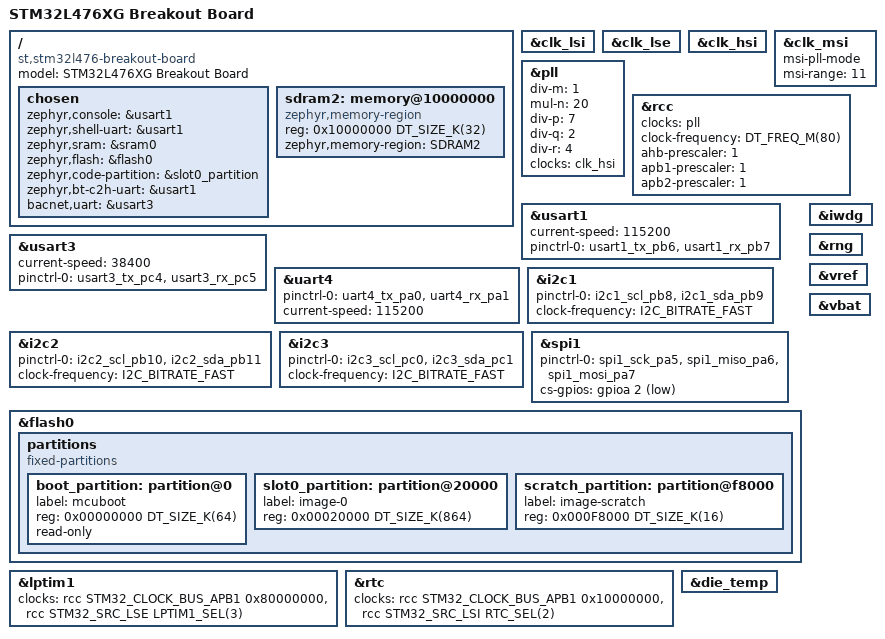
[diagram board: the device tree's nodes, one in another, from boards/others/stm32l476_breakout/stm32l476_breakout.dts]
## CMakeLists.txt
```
# SPDX-License-Identifier: Apache-2.0

set(SHIELD adafruit_2_8_tft_touch_v2)

cmake_minimum_required(VERSION 3.20.0)

# would be dope to define DBOARD_ROOT in here

find_package(Zephyr REQUIRED HINTS $ENV{ZEPHYR_BASE})
project(snowboard_press)

target_sources(app PRIVATE src/main.c)
target_sources(app PRIVATE src/console_cmds.c)

# Add custom linker section to relocate framebuffers to SRAM2
zephyr_linker_sources_ifdef(CONFIG_LV_Z_VBD_CUSTOM_SECTION
  SECTIONS dc_ram.ld)
```

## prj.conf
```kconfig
CONFIG_DEBUG=y

# peripherals
CONFIG_GPIO=y
CONFIG_I2C=y
CONFIG_SPI=y
CONFIG_SERIAL=y # from Modbus sample
CONFIG_UART_INTERRUPT_DRIVEN=y # from UART sample - needs serial interrupt enabled?
CONFIG_UART_LINE_CTRL=n # "Say no if not sure" so says zephyr documentation
CONFIG_UART_WIDE_DATA=y # BACNet messages are uint16


# log
CONFIG_LOG=y
#CONFIG_LOG_PRINTK=y
#CONFIG_LOG_MODE_IMMEDIATE=y

# shell / console
CONFIG_SHELL=y
CONFIG_GPIO_SHELL=y
CONFIG_I2C_SHELL=y
CONFIG_SPI_SHELL=y
CONFIG_STDOUT_CONSOLE=y
CONFIG_CONSOLE=y
CONFIG_PRINTK=y

# display / graphics
CONFIG_LVGL=y
CONFIG_LV_MEM_CUSTOM=y
CONFIG_LV_USE_LOG=y
CONFIG_LV_USE_LABEL=y
CONFIG_LV_USE_BTN=y
CONFIG_LV_USE_ARC=y
CONFIG_LV_USE_IMG=y
CONFIG_LV_USE_MONKEY=y
CONFIG_LV_FONT_MONTSERRAT_14=y
CONFIG_LV_Z_MEM_POOL_SIZE=16384
CONFIG_LV_Z_SHELL=y
CONFIG_MAIN_STACK_SIZE=2048
CONFIG_DISPLAY=y
CONFIG_DISPLAY_LOG_LEVEL_ERR=y

# Enable polling used by the event mechanism
#CONFIG_POLL=y

# Enable the state machine framework
#CONFIG_SMF=y
#CONFIG_SMF_ANCESTOR_SUPPORT=y
#CONFIG_SMF_INITIAL_TRANSITION=y

# Enable thread awareness for debugging tools supporting it
#CONFIG_DEBUG_THREAD_INFO=y

# enable to use thread names
#CONFIG_THREAD_NAME=y

# these configs imported from board_test_cli
#CONFIG_THREAD_MONITOR=y 
#CONFIG_INIT_STACKS=y 
CONFIG_BOOT_BANNER=y # this was n for board_test_cli
#CONFIG_THREAD_NAME=y 
#CONFIG_CBPRINTF_NANO=y
```

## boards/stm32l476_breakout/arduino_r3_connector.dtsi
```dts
/*
 * Copyright (c) 2019 Linaro Limited
 *
 * SPDX-License-Identifier: Apache-2.0
 */

/ {
	arduino_header: connector {
		compatible = "arduino-header-r3";
		#gpio-cells = <2>;
		gpio-map-mask = <0xffffffff 0xffffffc0>;
		gpio-map-pass-thru = <0 0x3f>;
		gpio-map = <0 0 &gpioc 5 0>,	/* A0 */
			   <1 0 &gpioc 4 0>,	/* A1 */
			   <2 0 &gpioc 3 0>,	/* A2 */
			   <3 0 &gpioc 2 0>,	/* A3 */
			   <4 0 &gpioc 1 0>,	/* A4 */
			   <5 0 &gpioc 0 0>,	/* A5 */
			   <6 0 &gpioa 1 0>,	/* D0 */
			   <7 0 &gpioa 0 0>,	/* D1 */
			   <8 0 &gpiod 14 0>,	/* D2 */
			   <9 0 &gpiob 0 0>,	/* D3 */
			   <10 0 &gpioa 3 0>,	/* D4 */
			   <11 0 &gpiob 4 0>,	/* D5 */
			   <12 0 &gpiob 1 0>,	/* D6 */
			   <13 0 &gpioc 7 0>,	/* D7 - MOVED FROM PA4 TO PC7 */
			   <14 0 &gpiob 12 0>,	/* D8 - MOVED FROM PB2 TO PB12 */
			   <15 0 &gpioa 15 0>,	/* D9 */
			   <16 0 &gpioa 2 0>,	/* D10 */
			   <17 0 &gpioa 7 0>,	/* D11 */
			   <18 0 &gpioa 6 0>,	/* D12 */
			   <19 0 &gpioa 5 0>,	/* D13 */
			   <20 0 &gpiob 9 0>,	/* D14 */
			   <21 0 &gpiob 8 0>;	/* D15 */
	};
};

arduino_i2c: &i2c1 {};
arduino_spi: &spi1 {};
arduino_serial: &uart4 {};
```

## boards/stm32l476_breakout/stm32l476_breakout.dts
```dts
/*
 * By Sam Burner 2025/06/18
 *
 * SPDX-License-Identifier: Apache-2.0
 */

 /dts-v1/;
#include <st\l4\stm32l476Xg.dtsi>
#include <st\l4\stm32l476r(c-e-g)tx-pinctrl.dtsi>
#include "arduino_r3_connector.dtsi"
#include <zephyr/dt-bindings/input/input-event-codes.h>

/ {
    model = "STM32L476XG Breakout Board";
    compatible = "st,stm32l476-breakout-board"; /* not sure if the "st," is an issue? possibly defined by vendor in yaml files */

    chosen {
		zephyr,console = &usart1;
		zephyr,shell-uart = &usart1;
		zephyr,sram = &sram0;
		zephyr,flash = &flash0;
		zephyr,code-partition = &slot0_partition;
		zephyr,bt-c2h-uart = &usart1; /* probably unnecessary */
	};

};

&clk_lsi {
	status = "okay";
};

&clk_lse {
	status = "okay";
};

&clk_hsi {
	status = "okay";
};

/* probably unnecessary, hopefully not a problem */
&clk_msi {
	status = "okay";
	msi-pll-mode;
	msi-range = <11>; /* 48MHz USB bus clk */
};

&pll {
	div-m = <1>;
	mul-n = <20>;
	div-p = <7>;
	div-q = <2>;
	div-r = <4>;
	clocks = <&clk_hsi>;
	status = "okay";
};

&rcc {
	clocks = <&pll>;
	clock-frequency = <DT_FREQ_M(80)>;
	ahb-prescaler = <1>;
	apb1-prescaler = <1>;
	apb2-prescaler = <1>;
};

&usart1 {
	current-speed = <115200>;
	pinctrl-0 = <&usart1_tx_pb6 &usart1_rx_pb7>;
	pinctrl-names = "default";
	status = "okay";
};

&usart3 {
	current-speed = <115200>;
	pinctrl-0 = <&usart3_tx_pc4 &usart3_rx_pc5>;
	pinctrl-names = "default";
	status = "okay";
};

&uart4 {
	pinctrl-0 = <&uart4_tx_pa0 &uart4_rx_pa1>;
	pinctrl-names = "default";
	current-speed = <115200>;
	status = "okay";
};

&i2c1 {
	pinctrl-0 = <&i2c1_scl_pb8 &i2c1_sda_pb9>;
	pinctrl-names = "default";
	status = "okay";
	clock-frequency = <I2C_BITRATE_FAST>;
};

&i2c2 {
	pinctrl-0 = <&i2c2_scl_pb10 &i2c2_sda_pb11>;
	pinctrl-names = "default";
	status = "okay";
	clock-frequency = <I2C_BITRATE_FAST>;
};

&i2c3 {
	pinctrl-0 = <&i2c3_scl_pc0 &i2c3_sda_pc1>;
	pinctrl-names = "default";
	status = "okay";
	clock-frequency = <I2C_BITRATE_FAST>;
};

&spi1 {
	pinctrl-0 = <&spi1_sck_pa5 &spi1_miso_pa6 &spi1_mosi_pa7>;
	pinctrl-names = "default";
	cs-gpios = <&gpioa 2 (GPIO_ACTIVE_LOW | GPIO_PULL_UP)>;
	status = "okay";
};

&flash0 {
	partitions {
		compatible = "fixed-partitions";
		#address-cells = <1>;
		#size-cells = <1>;

		boot_partition: partition@0 {
			label = "mcuboot";
			reg = <0x00000000 DT_SIZE_K(64)>;
			read-only;
		};

		/*
		 * The flash starting at offset 0x10000 and ending at
		 * offset 0x1ffff is reserved for use by the application.
		 */

		slot0_partition: partition@20000 {
			label = "image-0";
			reg = <0x00020000 DT_SIZE_K(864)>;
		};

		scratch_partition: partition@f8000 {
			label = "image-scratch";
			reg = <0x000F8000 DT_SIZE_K(16)>;
		};
	};
};

stm32_lp_tick_source: &lptim1 {
	clocks = <&rcc STM32_CLOCK_BUS_APB1 0x80000000>,
		 <&rcc STM32_SRC_LSE LPTIM1_SEL(3)>;
	status = "okay";
};

&rtc {
	clocks = <&rcc STM32_CLOCK_BUS_APB1 0x10000000>,
		 <&rcc STM32_SRC_LSI RTC_SEL(2)>;
	status = "okay";
};

&iwdg {
	status = "okay";
};

&rng {
	status = "okay";
};

&die_temp {
	status = "okay";
};

&vref {
	status = "okay";
};

&vbat {
	status = "okay";
};
```

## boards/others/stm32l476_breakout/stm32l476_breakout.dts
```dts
/*
 * By Sam Burner 2025/06/18
 *
 * SPDX-License-Identifier: Apache-2.0
 */

 /dts-v1/;
#include <st\l4\stm32l476Xg.dtsi>
#include <st\l4\stm32l476r(c-e-g)tx-pinctrl.dtsi>
#include "arduino_r3_connector.dtsi"
#include <zephyr/dt-bindings/input/input-event-codes.h>

/ {
    model = "STM32L476XG Breakout Board";
    compatible = "st,stm32l476-breakout-board"; /* not sure if the "st," is an issue? possibly defined by vendor in yaml files */

    chosen {
		zephyr,console = &usart1;
		zephyr,shell-uart = &usart1;
		zephyr,sram = &sram0;
		zephyr,flash = &flash0;
		zephyr,code-partition = &slot0_partition;
		zephyr,bt-c2h-uart = &usart1; /* probably unnecessary */
		bacnet,uart = &usart3;
	};

	sdram2: memory@10000000 {
		compatible = "zephyr,memory-region", "mmio-sram";
		device_type = "memory";
		reg = <0x10000000 DT_SIZE_K(32)>;
		zephyr,memory-region = "SDRAM2";
		status="okay";
	};

};

&clk_lsi {
	status = "okay";
};

&clk_lse {
	status = "okay";
};

&clk_hsi {
	status = "okay";
};

/* probably unnecessary, hopefully not a problem */
&clk_msi {
	status = "okay";
	msi-pll-mode;
	msi-range = <11>; /* 48MHz USB bus clk */
};

&pll {
	div-m = <1>;
	mul-n = <20>;
	div-p = <7>;
	div-q = <2>;
	div-r = <4>;
	clocks = <&clk_hsi>;
	status = "okay";
};

&rcc {
	clocks = <&pll>;
	clock-frequency = <DT_FREQ_M(80)>;
	ahb-prescaler = <1>;
	apb1-prescaler = <1>;
	apb2-prescaler = <1>;
};

&usart1 {
	current-speed = <115200>;
	pinctrl-0 = <&usart1_tx_pb6 &usart1_rx_pb7>;
	pinctrl-names = "default";
	status = "okay";
};

&usart3 {
	current-speed = <38400>;
	pinctrl-0 = <&usart3_tx_pc4 &usart3_rx_pc5>;
	pinctrl-names = "default";
	status = "okay";

};

&uart4 {
	pinctrl-0 = <&uart4_tx_pa0 &uart4_rx_pa1>;
	pinctrl-names = "default";
	current-speed = <115200>;
	status = "okay";
};

&i2c1 {
	pinctrl-0 = <&i2c1_scl_pb8 &i2c1_sda_pb9>;
	pinctrl-names = "default";
	status = "okay";
	clock-frequency = <I2C_BITRATE_FAST>;
};

&i2c2 {
	pinctrl-0 = <&i2c2_scl_pb10 &i2c2_sda_pb11>;
	pinctrl-names = "default";
	status = "okay";
	clock-frequency = <I2C_BITRATE_FAST>;
};

&i2c3 {
	pinctrl-0 = <&i2c3_scl_pc0 &i2c3_sda_pc1>;
	pinctrl-names = "default";
	status = "okay";
	clock-frequency = <I2C_BITRATE_FAST>;
};

&spi1 {
	pinctrl-0 = <&spi1_sck_pa5 &spi1_miso_pa6 &spi1_mosi_pa7>;
	pinctrl-names = "default";
	cs-gpios = <&gpioa 2 (GPIO_ACTIVE_LOW | GPIO_PULL_UP)>;
	status = "okay";
};

&flash0 {
	partitions {
		compatible = "fixed-partitions";
		#address-cells = <1>;
		#size-cells = <1>;

		boot_partition: partition@0 {
			label = "mcuboot";
			reg = <0x00000000 DT_SIZE_K(64)>;
			read-only;
		};

		/*
		 * The flash starting at offset 0x10000 and ending at
		 * offset 0x1ffff is reserved for use by the application.
		 */

		slot0_partition: partition@20000 {
			label = "image-0";
			reg = <0x00020000 DT_SIZE_K(864)>;
		};

		scratch_partition: partition@f8000 {
			label = "image-scratch";
			reg = <0x000F8000 DT_SIZE_K(16)>;
		};
	};
};

stm32_lp_tick_source: &lptim1 {
	clocks = <&rcc STM32_CLOCK_BUS_APB1 0x80000000>,
		 <&rcc STM32_SRC_LSE LPTIM1_SEL(3)>;
	status = "okay";
};

&rtc {
	clocks = <&rcc STM32_CLOCK_BUS_APB1 0x10000000>,
		 <&rcc STM32_SRC_LSI RTC_SEL(2)>;
	status = "okay";
};

&iwdg {
	status = "okay";
};

&rng {
	status = "okay";
};

&die_temp {
	status = "okay";
};

&vref {
	status = "okay";
};

&vbat {
	status = "okay";
};
```

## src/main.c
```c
#include "main.h"

// echo bot
#include <zephyr/kernel.h>
#include <zephyr/device.h>
#include <zephyr/drivers/uart.h>

#include <stdio.h>
#include <string.h>

#define MSG_SIZE 32

/* queue to store up to 10 messages (aligned to 4-byte boundary) */
K_MSGQ_DEFINE(uart_msgq, MSG_SIZE, 10, 4);

static const struct device *const uart_dev = DEVICE_DT_GET(DT_NODELABEL(usart3));

/* receive buffer used in UART ISR callback */
static uint8_t rx_buf[MSG_SIZE];
static int rx_buf_pos;


/*
 * Read characters from UART until line end is detected. Afterwards push the
 * data to the message queue.
 */
void serial_cb(const struct device *dev, void *user_data)
{
	uint8_t c;

	if (!uart_irq_update(uart_dev)) {
		return;
	}

	if (!uart_irq_rx_ready(uart_dev)) {
		return;
	}

	/* read until FIFO empty */
	while (uart_fifo_read(uart_dev, &c, 1) == 1) {
		if ((c == '\n' || c == '\r') && rx_buf_pos > 0) {

			/* if queue is full, message is silently dropped */
			k_msgq_put(&uart_msgq, &rx_buf, K_NO_WAIT);

			/* reset the buffer (it was copied to the msgq) */
			rx_buf_pos = 0;
		} else if (rx_buf_pos < (sizeof(rx_buf) - 1)) {
			rx_buf[rx_buf_pos++] = c;
		}
		/* else: characters beyond buffer size are dropped */
	}
}

/*
 * Print a null-terminated string character by character to the UART interface
 */
void print_uart(char *buf)
{
	int msg_len = strlen(buf);

	for (int i = 0; i < msg_len; i++) {
		uart_poll_out(uart_dev, buf[i]);
	}
}

/*BEGIN subsystem testing setup and globals*/

LOG_MODULE_REGISTER(main, LOG_LEVEL_INF);

const struct device *const dev_gpioa = DEVICE_DT_GET(DT_NODELABEL(gpioa));
const struct device *const dev_uart3 = DEVICE_DT_GET(DT_NODELABEL(usart3));
static struct gpio_callback alert_cb;

struct k_msgq eventq;
K_MSGQ_DEFINE(eventq, sizeof(uint32_t), 32, 1);


/*END subsystem testing setup and globals*/

/*BEGIN Subsystem testing functions*/
static void lv_relay1_callback(lv_event_t *e)
{
	ARG_UNUSED(e);

	/*add TOGGLE_RELAY1 to queue*/
	uint32_t msg = TOGGLE_RELAY1;
	k_msgq_put(&eventq, &msg, K_NO_WAIT);

}

static void lv_relay2_callback(lv_event_t *e)
{
	ARG_UNUSED(e);
	/*add TOGGLE_RELAY2 to queue*/
	uint32_t msg = TOGGLE_RELAY2;
	k_msgq_put(&eventq, &msg, K_NO_WAIT);
}

void alert_callback(const struct device *dev, struct gpio_callback *cb, uint32_t pins)
{
	/*add ALERT to queue*/
	uint32_t msg = ALERT;
	k_msgq_put(&eventq, &msg, K_NO_WAIT);
}

/*
 * Print an un-terminated byte array to the UART interface
 */
void print_byte_array(uint8_t *buf, uint8_t buf_size)
{
	for (int i = 0; i < buf_size; i++) {
		uart_poll_out(uart_dev, buf[i]);
	}
}


/*TODO read request callback*/
/*
different behavior based on int or float
zone, parameter, channel, data, float/int
this initially will be a hardcoded message with static crc sections

assemble message

send message over UART (or queue event to send message?)

*/

/*END subsystem testing callbacks*/



int main(void) {

	/*BEGIN subsystem testing variable init*/
	
	const struct device *display_dev;

	char alert_str[11] = {0};
	char* relay1_str = {"Toggle Relay 1"};
	char* relay2_str = {"Toggle Relay 2"};

	lv_obj_t *alert_label;
	lv_obj_t *relay1_label;
	lv_obj_t *relay2_label;

	int32_t ret = 0;

	uint32_t alert_count = 0;
	
	/*END subsystem testing variable init*/

    display_dev = DEVICE_DT_GET(DT_CHOSEN(zephyr_display));
	if (!device_is_ready(display_dev)) {
		LOG_ERR("Device not ready, aborting test");
		return 0;
	}


	lv_obj_t *relay1_button;
	relay1_button = lv_btn_create(lv_scr_act());
	lv_obj_align(relay1_button, LV_ALIGN_CENTER, 0, 45);
	lv_obj_add_event_cb(relay1_button, lv_relay1_callback, LV_EVENT_CLICKED, NULL);
	relay1_label = lv_label_create(relay1_button);

	lv_obj_t *relay2_button;
	relay2_button = lv_btn_create(lv_scr_act());
	lv_obj_align(relay2_button, LV_ALIGN_CENTER, 0, 0);
	lv_obj_add_event_cb(relay2_button, lv_relay2_callback, LV_EVENT_CLICKED, NULL);
	relay2_label = lv_label_create(relay2_button);

	alert_label = lv_label_create(lv_scr_act());
	lv_obj_align(alert_label, LV_ALIGN_CENTER, 0, -45);

	/*TODO process value indicators - top/bottom setpoint and analog value*/


	/*set up gpio pins*/
	if (!device_is_ready(dev_gpioa)) {
		LOG_ERR("GPIOA not ready");
	}

	/* configure relay1 pin as output and set low*/
	ret = gpio_pin_configure(dev_gpioa, RELAY1_PIN, GPIO_OUTPUT_LOW);
	if (ret != 0) {
		LOG_ERR("Relay 1 pin failed to configure");
	}

	/*configure relay2 pin as output and set low*/
	ret = gpio_pin_configure(dev_gpioa, RELAY2_PIN, GPIO_OUTPUT_LOW);
	if (ret != 0) {
		LOG_ERR("Relay 2 pin failed to configure");
	}

	/*configure alert as input, active high (NOTE: Needs hardware pull up)*/
	ret = gpio_pin_configure(dev_gpioa, ALERT_PIN, GPIO_INPUT);
	if (ret != 0) {
		LOG_ERR("ERROR: failed to configure alert pin as input");
	}

	ret = gpio_pin_interrupt_configure(dev_gpioa, ALERT_PIN, GPIO_INT_EDGE_TO_ACTIVE);
	if (ret != 0) {
		LOG_ERR("Alert pin interrupt failed to configure");
	}

	/*register alert callback*/
	gpio_init_callback(&alert_cb, alert_callback, BIT(ALERT_PIN));
	gpio_add_callback(dev_gpioa, &alert_cb);

	/*TODO not sure if required - initial ready to clear alert flag*/

	lv_label_set_text(relay1_label, relay1_str);
	lv_obj_align(relay1_label, LV_ALIGN_CENTER, 0, 0);

	lv_label_set_text(relay2_label, relay2_str);
	lv_obj_align(relay2_label, LV_ALIGN_CENTER, 0, 0);

	lv_label_set_text(alert_label, alert_str);

    /*start lvgl task handler and turn off display blanking*/
	lv_task_handler();
	display_blanking_off(display_dev);



	/*START echo bot*/ 

	char tx_buf[MSG_SIZE];

	if (!device_is_ready(uart_dev)) {
		printk("UART device not found!");
		return 0;
	}

	/* configure interrupt and callback to receive data */
	/* TODO this doesn't have to be an interrupt - we can poll for response after a read request is sent */
	ret = uart_irq_callback_user_data_set(uart_dev, serial_cb, NULL);

	if (ret < 0) {
		if (ret == -ENOTSUP) {
			printk("Interrupt-driven UART API support not enabled\n");
		} else if (ret == -ENOSYS) {
			printk("UART device does not support interrupt-driven API\n");
		} else {
			printk("Error setting UART callback: %d\n", ret);
		}
		return 0;
	}
	uart_irq_rx_enable(uart_dev);

	print_uart("Hello! I'm your echo bot.\r\n");
	print_uart("Tell me something and press enter:\r\n");

	/*END echo bot*/


    while (1) {
		
		uint32_t msg = 0;

		/*START echo bot*/
		/*TODO this is just going to hog the whole event loop*/
		/* indefinitely wait for input from the user */
		/*
		while (k_msgq_get(&uart_msgq, &tx_buf, K_FOREVER) == 0) {
			print_uart("Echo: ");
			print_byte_array(tx_buf, BACNET_MSG_SIZE);
			print_uart("\r\n");
		}
		*/
		/*END echo bot*/

		/*get message from queue*/
		ret = k_msgq_get(&eventq, &msg, K_NO_WAIT);
		if (ret == 0) {
			LOG_INF("msg: %x\r\n", msg);
		}

		/*
		TODO: button that sends a READ watlow message for process analog value (top)
		send read request (int or float?)
		queue event for sending read request to watlow
		*/
		/*
		TODO event handler for writing watlow data
		call send_watlow_command
		if read request, queue event for reading watlow data
		*/
		/*
		TODO event handler for reading watlow data
		call read_watlow_data
		queue event for updating watlow indicator with relevant data
		*/
		/*
		TODO event handler for updating watlow indicators
		*/
		/*
		TODO: button that sends a READ watlow message for process analog value (bottom)
		*/
		/*
		TODO: button that sends a READ watlow message for process setpoint value (top)
		*/
		/*
		TODO: button that sends a READ watlow message for process setpoint value (bottom)
		*/
		/*
		TODO: button that sends a WRITE watlow message (+1) for process setpoint value (top)
		*/
		/*
		TODO: button that sends a WRITE watlow message (+1) for process setpoint value (bottom)
		*/

		/*handle ALERT msg*/
		if (msg & ALERT) {
			LOG_INF("ALERT message received");
			sprintf(alert_str, "%d", ++alert_count);
			LOG_INF("Printing count...");
			lv_label_set_text(alert_label, alert_str);
		}
		/*handle TOGGLE RELAY1 msg*/
		if (msg & TOGGLE_RELAY1) {
			ret = gpio_pin_toggle(dev_gpioa, RELAY1_PIN);
			if (ret != 0) {
				LOG_ERR("Error toggling relay 1\r\n");
			}
		} 
		
		/*handle TOGGLE RELAY2 msg*/
		if (msg & TOGGLE_RELAY2) {
			ret = gpio_pin_toggle(dev_gpioa, RELAY2_PIN);
			if (ret != 0) {
				LOG_ERR("Error toggling relay 2\r\n");
			}
		}

		lv_task_handler();
		
		k_sleep(K_MSEC(10));
	}

    return 0;
}
```

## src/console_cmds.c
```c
/* 8/6/2025 */
#include "main.h"

#include <stdlib.h>
#include <ctype.h>
#include <string.h>

/*TODO bacnet read_int*/

/*TODO bacnet write_int*/

/*TODO bacnet read_float*/

/*TODO bacnet write_float*/

/*TODO create bacnet test command subset*/
```

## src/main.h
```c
#pragma once

#include <zephyr/device.h>
#include <zephyr/devicetree.h>
#include <zephyr/drivers/display.h>
#include <zephyr/drivers/gpio.h>
#include <zephyr/drivers/uart.h>
#include <zephyr/kernel.h>
#include <zephyr/logging/log.h>
#include <zephyr/shell/shell.h>
#include <zephyr/sys/util.h>
#include <lvgl.h>
#include <lvgl_input_device.h>
#include <stdio.h>
#include <string.h>

#define BACNET_MSG_SIZE (16)

#define ALERT_PIN  ((gpio_pin_t) 8u)
#define RELAY1_PIN ((gpio_pin_t) 9u)
#define RELAY2_PIN ((gpio_pin_t) 10u)

#define ALERT         ((1ul) << (0))
#define TOGGLE_RELAY1 ((1ul) << (1))
#define TOGGLE_RELAY2 ((1ul) << (2))
#define BACNET_RX     ((1ul) << (3))
```
